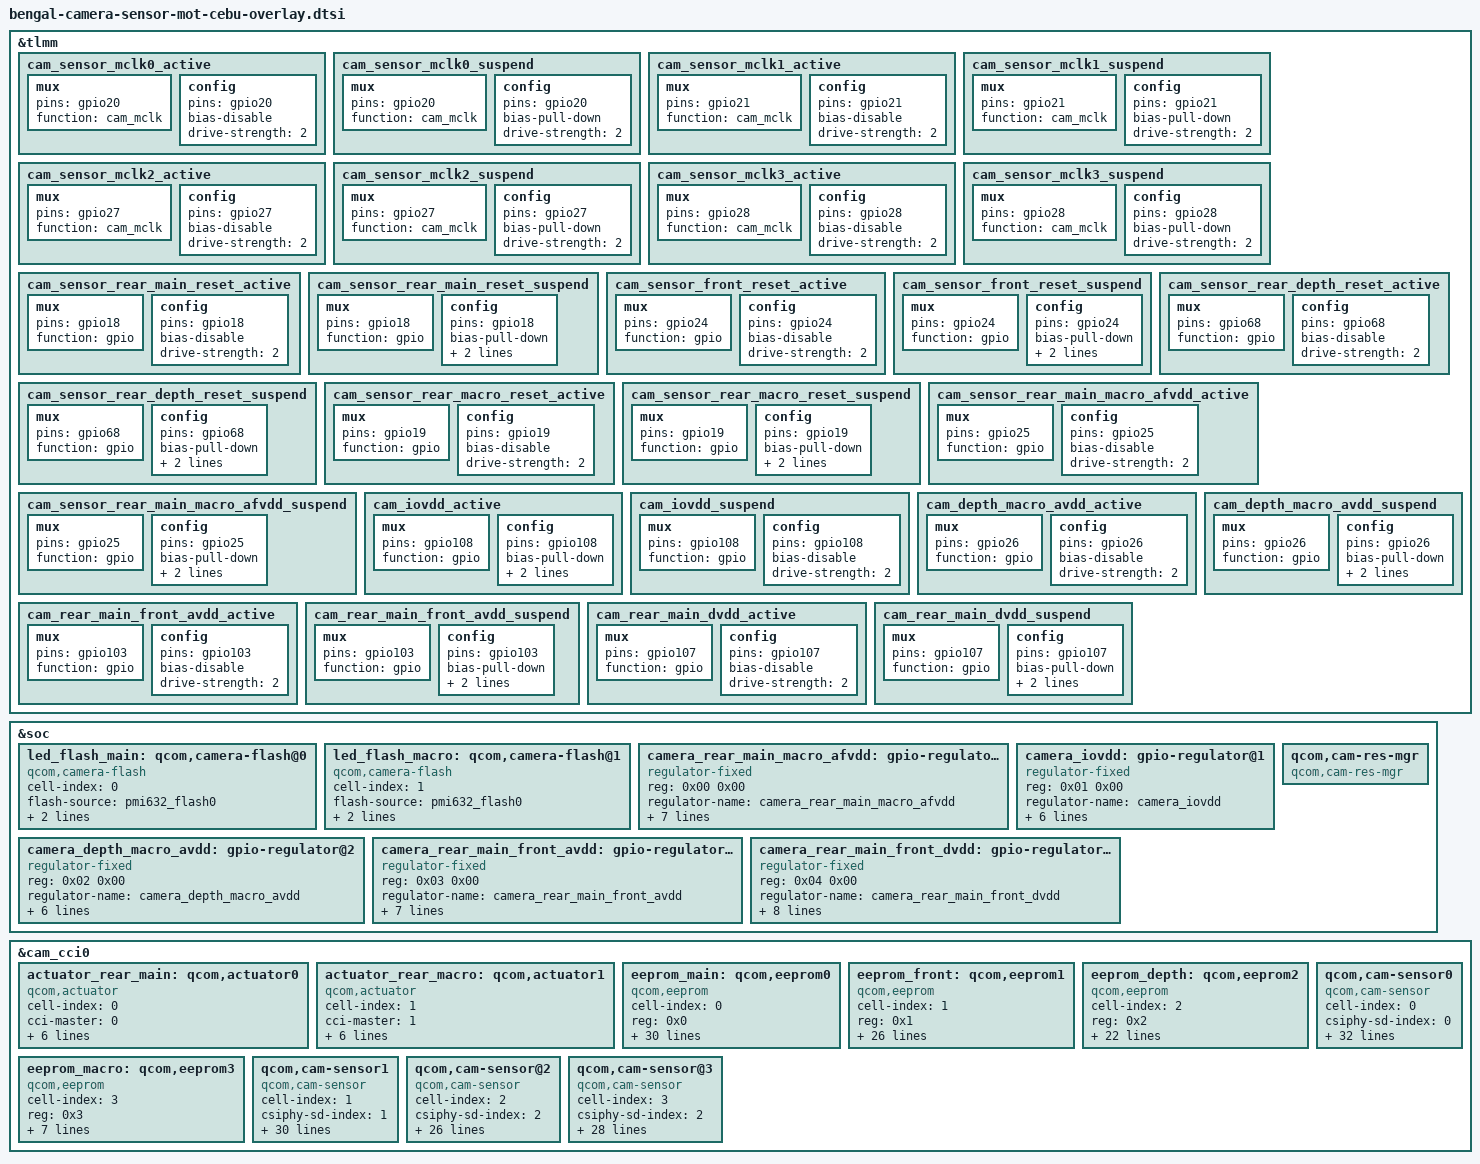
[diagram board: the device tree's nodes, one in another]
#include <dt-bindings/clock/qcom,gcc-bengal.h>


&tlmm {
	cam_sensor_mclk0_active: cam_sensor_mclk0_active {
		mux {
			pins = "gpio20";
			function = "cam_mclk";
		};

		config {
			pins = "gpio20";
			bias-disable; /* No PULL */
			drive-strength = <2>; /* 2 MA */
		};
	};

	cam_sensor_mclk0_suspend: cam_sensor_mclk0_suspend {
		mux {
			pins = "gpio20";
			function = "cam_mclk";
		};

		config {
			pins = "gpio20";
			bias-pull-down;
			drive-strength = <2>; /* 2 MA */
		};
	};

	cam_sensor_mclk1_active: cam_sensor_mclk1_active {
		mux {
			pins = "gpio21";
			function = "cam_mclk";
		};

		config {
			pins = "gpio21";
			bias-disable; /* No PULL */
			drive-strength = <2>; /* 2 MA */
		};
	};

	cam_sensor_mclk1_suspend: cam_sensor_mclk1_suspend {
		mux {
			pins = "gpio21";
			function = "cam_mclk";
		};

		config {
			pins = "gpio21";
			bias-pull-down;
			drive-strength = <2>; /* 2 MA */
		};
	};

	cam_sensor_mclk2_active: cam_sensor_mclk2_active {
		mux {
			pins = "gpio27";
			function = "cam_mclk";
		};

		config {
			pins = "gpio27";
			bias-disable; /* No PULL */
			drive-strength = <2>; /* 2 MA */
		};
	};

	cam_sensor_mclk2_suspend: cam_sensor_mclk2_suspend {
		mux {
			pins = "gpio27";
			function = "cam_mclk";
		};

		config {
			pins = "gpio27";
			bias-pull-down;
			drive-strength = <2>; /* 2 MA */
		};
	};

	cam_sensor_mclk3_active: cam_sensor_mclk3_active {
		mux {
			pins = "gpio28";
			function = "cam_mclk";
		};

		config {
			pins = "gpio28";
			bias-disable; /* No PULL */
			drive-strength = <2>; /* 2 MA */
		};
	};

	cam_sensor_mclk3_suspend: cam_sensor_mclk3_suspend {
		mux {
			pins = "gpio28";
			function = "cam_mclk";
		};

		config {
			pins = "gpio28";
			bias-pull-down;
			drive-strength = <2>; /* 2 MA */
		};
	};

	cam_sensor_rear_main_reset_active: cam_sensor_rear_main_reset_active {
		mux {
			pins = "gpio18";
			function = "gpio";
		};

		config {
			pins = "gpio18";
			bias-disable; /* No PULL */
			drive-strength = <2>; /* 2 MA */
		};
	};

	cam_sensor_rear_main_reset_suspend: cam_sensor_rear_main_reset_suspend {
		mux {
			pins = "gpio18";
			function = "gpio";
		};

		config {
			pins = "gpio18";
			bias-pull-down; /* PULL DOWN */
			drive-strength = <2>; /* 2 MA */
			output-low;
		};
	};

	cam_sensor_front_reset_active: cam_sensor_front_reset_active {
		mux {
			pins = "gpio24";
			function = "gpio";
		};

		config {
			pins = "gpio24";
			bias-disable; /* No PULL */
			drive-strength = <2>; /* 2 MA */
		};
	};

	cam_sensor_front_reset_suspend: cam_sensor_front_reset_suspend {
		mux {
			pins = "gpio24";
			function = "gpio";
		};

		config {
			pins = "gpio24";
			bias-pull-down; /* PULL DOWN */
			drive-strength = <2>; /* 2 MA */
			output-low;
		};
	};

	cam_sensor_rear_depth_reset_active: cam_sensor_rear_depth_reset_active {
		mux {
			pins = "gpio68";
			function = "gpio";
		};

		config {
			pins = "gpio68";
			bias-disable; /* No PULL */
			drive-strength = <2>; /* 2 MA */
		};
	};

	cam_sensor_rear_depth_reset_suspend: cam_sensor_rear_depth_reset_suspend {
		mux {
			pins = "gpio68";
			function = "gpio";
		};

		config {
			pins = "gpio68";
			bias-pull-down; /* PULL DOWN */
			drive-strength = <2>; /* 2 MA */
			output-low;
		};
	};

	cam_sensor_rear_macro_reset_active: cam_sensor_rear_macro_reset_active {
		mux {
			pins = "gpio19";
			function = "gpio";
		};

		config {
			pins = "gpio19";
			bias-disable; /* No PULL */
			drive-strength = <2>; /* 2 MA */
		};
	};

	cam_sensor_rear_macro_reset_suspend: cam_sensor_rear_macro_reset_suspend {
		mux {
			pins = "gpio19";
			function = "gpio";
		};

		config {
			pins = "gpio19";
			bias-pull-down; /* PULL DOWN */
			drive-strength = <2>; /* 2 MA */
			output-low;
		};
	};

	cam_sensor_rear_main_macro_afvdd_active: cam_sensor_rear_main_macro_afvdd_active {
		mux {
			pins = "gpio25";
			function = "gpio";
		};

		config {
			pins = "gpio25";
			bias-disable; /* No PULL */
			drive-strength = <2>; /* 2 MA */
		};
	};

	cam_sensor_rear_main_macro_afvdd_suspend: cam_sensor_rear_main_macro_afvdd_suspend {
		mux {
			pins = "gpio25";
			function = "gpio";
		};

		config {
			pins = "gpio25";
			bias-pull-down; /* PULL DOWN */
			drive-strength = <2>; /* 2 MA */
			output-low;
		};
	};

	cam_iovdd_active: cam_iovdd_active {
		mux {
			pins = "gpio108";
			function = "gpio";
		};

		config {
			pins = "gpio108";
			bias-pull-down; /* PULL DOWN */
			drive-strength = <2>; /* 2 MA */
			output-low;
		};
	};

	cam_iovdd_suspend: cam_iovdd_suspend {
		mux {
			pins = "gpio108";
			function = "gpio";
		};

		config {
			pins = "gpio108";
			bias-disable; /* No PULL */
			drive-strength = <2>; /* 2 MA */
		};
	};

	cam_depth_macro_avdd_active: cam_depth_macro_avdd_active {
		mux {
			pins = "gpio26";
			function = "gpio";
		};

		config {
			pins = "gpio26";
			bias-disable; /* No PULL */
			drive-strength = <2>; /* 2 MA */
		};
	};

	cam_depth_macro_avdd_suspend: cam_depth_macro_avdd_suspend {
		mux {
			pins = "gpio26";
			function = "gpio";
		};

		config {
			pins = "gpio26";
			bias-pull-down; /* PULL DOWN */
			drive-strength = <2>; /* 2 MA */
			output-low;
		};
	};

	cam_rear_main_front_avdd_active: cam_rear_main_front_avdd_active {
		mux {
			pins = "gpio103";
			function = "gpio";
		};

		config {
			pins = "gpio103";
			bias-disable; /* No PULL */
			drive-strength = <2>; /* 2 MA */
		};
	};

	cam_rear_main_front_avdd_suspend: cam_rear_main_front_avdd_suspend {
		mux {
			pins = "gpio103";
			function = "gpio";
		};

		config {
			pins = "gpio103";
			bias-pull-down; /* PULL DOWN */
			drive-strength = <2>; /* 2 MA */
			output-low;
		};
	};

	cam_rear_main_dvdd_active: cam_rear_main_dvdd_active {
		mux {
			pins = "gpio107";
			function = "gpio";
		};

		config {
			pins = "gpio107";
			bias-disable; /* No PULL */
			drive-strength = <2>; /* 2 MA */
		};
	};

	cam_rear_main_dvdd_suspend: cam_rear_main_dvdd_suspend {
		mux {
			pins = "gpio107";
			function = "gpio";
		};

		config {
			pins = "gpio107";
			bias-pull-down; /* PULL DOWN */
			drive-strength = <2>; /* 2 MA */
			output-low;
		};
	};
};

&soc {
	led_flash_main: qcom,camera-flash@0 {
		cell-index = <0>;
		compatible = "qcom,camera-flash";
		flash-source  = <&pmi632_flash0>;
		torch-source  = <&pmi632_torch0>;
		switch-source = <&pmi632_switch0>;
		status = "ok";
	};

	led_flash_macro: qcom,camera-flash@1 {
		cell-index = <1>;
		compatible = "qcom,camera-flash";
		flash-source  = <&pmi632_flash0>;
		torch-source  = <&pmi632_torch0>;
		switch-source = <&pmi632_switch0>;
		status = "ok";
	};

	camera_rear_main_macro_afvdd: gpio-regulator@0 {
		compatible = "regulator-fixed";
		reg = <0x00 0x00>;
		regulator-name = "camera_rear_main_macro_afvdd";
		regulator-min-microvolt = <2800000>;
		regulator-max-microvolt = <2800000>;
		regulator-enable-ramp-delay = <233>;
		enable-active-high;
		gpio = <&tlmm 25 0>;
		pinctrl-names = "default";
		pinctrl-0 = <&cam_sensor_rear_main_macro_afvdd_active>;
		//pinctrl-1 = <&cam_sensor_rear_main_macro_afvdd_suspend>;
	};

	camera_iovdd: gpio-regulator@1 {
		compatible = "regulator-fixed";
		reg = <0x01 0x00>;
		regulator-name = "camera_iovdd";
		regulator-min-microvolt = <1800000>;
		regulator-max-microvolt = <1800000>;
		regulator-enable-ramp-delay = <233>;
		//enable-active-high;//fff
		gpio = <&tlmm 108 0>;
		pinctrl-names = "default";
		pinctrl-0 = <&cam_iovdd_active>;
		//pinctrl-1 = <&cam_iovdd_suspend>;
		vin-supply = <&L9A>;
	};

	camera_depth_macro_avdd: gpio-regulator@2 {
		compatible = "regulator-fixed";
		reg = <0x02 0x00>;
		regulator-name = "camera_depth_macro_avdd";
		regulator-min-microvolt = <2800000>;
		regulator-max-microvolt = <2800000>;
		regulator-enable-ramp-delay = <233>;
		enable-active-high;
		gpio = <&tlmm 26 0>;
		pinctrl-names = "default";
		pinctrl-0 = <&cam_depth_macro_avdd_active>;
		//pinctrl-1 = <&cam_depth_macro_avdd_suspend>;
	};

	camera_rear_main_front_avdd: gpio-regulator@3 {
		compatible = "regulator-fixed";
		reg = <0x03 0x00>;
		regulator-name = "camera_rear_main_front_avdd";
		regulator-min-microvolt = <2800000>;
		regulator-max-microvolt = <2800000>;
		regulator-enable-ramp-delay = <233>;
		enable-active-high;
		gpio = <&tlmm 103 0>;
		pinctrl-names = "default";
		pinctrl-0 = <&cam_rear_main_front_avdd_active>;
		pinctrl-1 = <&cam_rear_main_front_avdd_suspend>;
	};
	/****************************************
	*	GPIO_80 low for rear main dvdd  *
	*	GPIO_80 high for front dvdd     *
	*****************************************/
	camera_rear_main_front_dvdd: gpio-regulator@4 {
		compatible = "regulator-fixed";
		reg = <0x04 0x00>;
		regulator-name = "camera_rear_main_front_dvdd";
		regulator-min-microvolt = <1200000>;
		regulator-max-microvolt = <1200000>;
		regulator-enable-ramp-delay = <233>;
		enable-active-high;
		gpio = <&tlmm 107 0>;
		pinctrl-names = "default";
		pinctrl-0 = <&cam_rear_main_dvdd_active>;
		pinctrl-1 = <&cam_rear_main_dvdd_suspend>;
		vin-supply = <&S6A>;
	};

	qcom,cam-res-mgr {
		compatible = "qcom,cam-res-mgr";
		status = "ok";
	};
};

&cam_cci0 {

	actuator_rear_main: qcom,actuator0 {
		cell-index = <0>;
		compatible = "qcom,actuator";
		cci-master = <0>;
		cam_vaf-supply = <&camera_rear_main_macro_afvdd>;
		regulator-names = "cam_vaf";
		rgltr-cntrl-support;
		rgltr-min-voltage = <2800000>;
		rgltr-max-voltage = <2800000>;
		rgltr-load-current = <100000>;
		status = "ok";
	};

	actuator_rear_macro: qcom,actuator1 {
		cell-index = <1>;
		compatible = "qcom,actuator";
		cci-master = <1>;
		cam_vaf-supply = <&camera_rear_main_macro_afvdd>;
		regulator-names = "cam_vaf";
		rgltr-cntrl-support;
		rgltr-min-voltage = <2800000>;
		rgltr-max-voltage = <2800000>;
		rgltr-load-current = <100000>;
		status = "ok";
	};

	/* ov64b rear main*/
	eeprom_main: qcom,eeprom0 {
		cell-index = <0>;
		reg = <0x0>;
		compatible = "qcom,eeprom";
		cam_vaf-supply = <&camera_rear_main_macro_afvdd>;
		cam_vio-supply = <&camera_iovdd>;
		cam_vana-supply = <&camera_rear_main_front_avdd>;
		cam_vdig-supply = <&camera_rear_main_front_dvdd>;
		cam_clk-supply = <&gcc_camss_top_gdsc>;
		regulator-names = "cam_vaf", "cam_vio", "cam_vana", "cam_vdig",
			"cam_clk";
		rgltr-cntrl-support;
		rgltr-min-voltage = <2800000 1800000 2800000 1200000 0>;
		rgltr-max-voltage = <2800000 1800000 2800000 1200000 0>;
		rgltr-load-current = <100000 120000 80000 1200000 0>;
		gpio-no-mux = <0>;
		pinctrl-names = "cam_default", "cam_suspend";
		pinctrl-0 = <&cam_sensor_mclk0_active
				&cam_sensor_rear_main_reset_active>;
		pinctrl-1 = <&cam_sensor_mclk0_suspend
				&cam_sensor_rear_main_reset_suspend>;
		gpios = <&tlmm 20 0>,
			<&tlmm 18 0>,
			<&tlmm 80 0>;
		gpio-reset = <1>;
		gpio-custom1 = <2>;//vdig active-low
		gpio-req-tbl-num = <0 1 2>;
		gpio-req-tbl-flags = <1 0 0>;
		gpio-req-tbl-label = "CAMIF_MCLK0",
					"CAM_RESET0",
					"CAM_DVDD_SEL0";
		cci-master = <0>;
		status = "ok";
		clocks = <&gcc GCC_CAMSS_MCLK0_CLK>;
		clock-names = "cam_clk";
		clock-cntl-level = "turbo";
		clock-rates = <24000000>;
	};

	/* ov16a1q front*/
	eeprom_front: qcom,eeprom1 {
		cell-index = <1>;
		reg = <0x1>;
		compatible = "qcom,eeprom";
		cam_vio-supply = <&camera_iovdd>;
		cam_vana-supply = <&camera_rear_main_front_avdd>;
		cam_vdig-supply = <&camera_rear_main_front_dvdd>;
		cam_clk-supply = <&gcc_camss_top_gdsc>;
		regulator-names = "cam_vio", "cam_vana", "cam_vdig",
			"cam_clk";
		rgltr-cntrl-support;
		rgltr-min-voltage = <1800000 2800000 1200000 0>;
		rgltr-max-voltage = <1800000 2800000 1200000 0>;
		rgltr-load-current = <120000 80000 1200000 0>;
		gpio-no-mux = <0>;
		pinctrl-names = "cam_default", "cam_suspend";
		pinctrl-0 = <&cam_sensor_mclk2_active
				&cam_sensor_front_reset_active>;
		pinctrl-1 = <&cam_sensor_mclk2_suspend
				&cam_sensor_front_reset_suspend>;
		gpios = <&tlmm 27 0>,
			<&tlmm 24 0>,
			<&tlmm 80 0>;
		gpio-reset = <1>;
		gpio-custom1 = <2>;/*vdig active-high */
		gpio-req-tbl-num = <0 1 2>;
		gpio-req-tbl-flags = <1 0 0>;
		gpio-req-tbl-label = "CAMIF_MCLK2",
					"CAM_RESET1",
					"CAM_DVDD_SEL1";
		cci-master = <0>;
		status = "ok";
		clocks = <&gcc GCC_CAMSS_MCLK2_CLK>;
		clock-names = "cam_clk";
		clock-cntl-level = "turbo";
		clock-rates = <24000000>;
	};

 	/* ov02b1b rear depth*/
	eeprom_depth: qcom,eeprom2 {
		cell-index = <2>;
		reg = <0x2>;
		compatible = "qcom,eeprom";
		cam_vio-supply = <&camera_iovdd>;
		cam_vana-supply = <&camera_depth_macro_avdd>;
		cam_clk-supply = <&gcc_camss_top_gdsc>;
		regulator-names = "cam_vio", "cam_vana", "cam_clk";
		rgltr-cntrl-support;
		rgltr-min-voltage = <1800000 2800000 0>;
		rgltr-max-voltage = <1800000 2800000 0>;
		rgltr-load-current = <120000 80000 0>;
		gpio-no-mux = <0>;
		pinctrl-names = "cam_default", "cam_suspend";
		pinctrl-0 = <&cam_sensor_mclk3_active
				&cam_sensor_rear_depth_reset_active>;
		pinctrl-1 = <&cam_sensor_mclk3_suspend
				&cam_sensor_rear_depth_reset_suspend>;
		gpios = <&tlmm 28 0>,
			<&tlmm 68 0>;
		gpio-reset = <1>;
		gpio-req-tbl-num = <0 1>;
		gpio-req-tbl-flags = <1 0>;
		gpio-req-tbl-label = "CAMIF_MCLK3",
					"CAM_RESET2";
		cci-master = <1>;
		status = "ok";
		clocks = <&gcc GCC_CAMSS_MCLK3_CLK>;
		clock-names = "cam_clk";
		clock-cntl-level = "turbo";
		clock-rates = <24000000>;
	};

	/* ov02b10 rear macro*/
	eeprom_macro: qcom,eeprom3 {
		cell-index = <3>;
		reg = <0x3>;
		compatible = "qcom,eeprom";
		cci-master = <1>;
		cam_vio-supply = <&camera_iovdd>;
		regulator-names = "cam_vio";
		rgltr-cntrl-support;
		rgltr-min-voltage = <1800000>;
		rgltr-max-voltage = <1800000>;
		rgltr-load-current = <120000>;
		status = "ok";
	};

	/* ov64b rear main */
	qcom,cam-sensor0 {
		cell-index = <0>;
		compatible = "qcom,cam-sensor";
		csiphy-sd-index = <0>;
		sensor-position-roll = <90>;
		sensor-position-pitch = <0>;
		sensor-position-yaw = <180>;
		actuator-src = <&actuator_rear_main>;
		led-flash-src = <&led_flash_main>;
		eeprom-src = <&eeprom_main>;
		cam_vio-supply = <&camera_iovdd>;
		cam_vana-supply = <&camera_rear_main_front_avdd>;
		cam_vdig-supply = <&camera_rear_main_front_dvdd>;
		cam_clk-supply = <&gcc_camss_top_gdsc>;
		regulator-names = "cam_vio", "cam_vana", "cam_vdig",
			"cam_clk";
		rgltr-cntrl-support;
		rgltr-min-voltage = <1800000 2800000 1200000 0>;
		rgltr-max-voltage = <1800000 2800000 1200000 0>;
		rgltr-load-current = <120000 80000 1200000 0>;
		gpio-no-mux = <0>;
		pinctrl-names = "cam_default", "cam_suspend";
		pinctrl-0 = <&cam_sensor_mclk0_active
				&cam_sensor_rear_main_reset_active>;
		pinctrl-1 = <&cam_sensor_mclk0_suspend
				&cam_sensor_rear_main_reset_suspend>;
		gpios = <&tlmm 20 0>,
			<&tlmm 18 0>,
			<&tlmm 80 0>;
		gpio-reset = <1>;
		gpio-custom1 = <2>;//vdig active-low
		gpio-req-tbl-num = <0 1 2>;
		gpio-req-tbl-flags = <1 0 0>;
		gpio-req-tbl-label = "CAMIF_MCLK0",
					"CAM_RESET0",
					"CAM_DVDD_SEL0";
		cci-master = <0>;
		status = "ok";
		clocks = <&gcc GCC_CAMSS_MCLK0_CLK>;
		clock-names = "cam_clk";
		clock-cntl-level = "turbo";
		clock-rates = <24000000>;
	};

	 /* ov16a1q & s5k4h7 front */
	qcom,cam-sensor1 {
		cell-index = <1>;
		compatible = "qcom,cam-sensor";
		csiphy-sd-index = <1>;
		sensor-position-roll = <270>;
		sensor-position-pitch = <0>;
		sensor-position-yaw = <0>;
		eeprom-src = <&eeprom_front>;
		cam_vio-supply = <&camera_iovdd>;
		cam_vana-supply = <&camera_rear_main_front_avdd>;
		cam_vdig-supply = <&camera_rear_main_front_dvdd>;
		cam_clk-supply = <&gcc_camss_top_gdsc>;
		regulator-names = "cam_vio", "cam_vana", "cam_vdig",
			"cam_clk";
		rgltr-cntrl-support;
		rgltr-min-voltage = <1800000 2800000 1200000 0>;
		rgltr-max-voltage = <1800000 2800000 1200000 0>;
		rgltr-load-current = <120000 80000 1200000 0>;
		gpio-no-mux = <0>;
		pinctrl-names = "cam_default", "cam_suspend";
		pinctrl-0 = <&cam_sensor_mclk2_active
				&cam_sensor_front_reset_active>;
		pinctrl-1 = <&cam_sensor_mclk2_suspend
				&cam_sensor_front_reset_suspend>;
		gpios = <&tlmm 27 0>,
			<&tlmm 24 0>,
			<&tlmm 80 0>;
		gpio-reset = <1>;
		gpio-custom1 = <2>;/*vdig active-high */
		gpio-req-tbl-num = <0 1 2>;
		gpio-req-tbl-flags = <1 0 0>;
		gpio-req-tbl-label = "CAMIF_MCLK2",
					"CAM_RESET1",
					"CAM_DVDD_SEL1";
		cci-master = <0>;
		status = "ok";
		clocks = <&gcc GCC_CAMSS_MCLK2_CLK>;
		clock-names = "cam_clk";
		clock-cntl-level = "turbo";
		clock-rates = <24000000>;
	};

	 /* ov02b1b depth*/

	qcom,cam-sensor@2 {
		cell-index = <2>;
		compatible = "qcom,cam-sensor";
		csiphy-sd-index = <2>;
		sensor-position-roll = <90>;
		sensor-position-pitch = <0>;
		sensor-position-yaw = <180>;
		eeprom-src = <&eeprom_depth>;
		cam_vio-supply = <&camera_iovdd>;
		cam_vana-supply = <&camera_depth_macro_avdd>;
		cam_clk-supply = <&gcc_camss_top_gdsc>;
		regulator-names = "cam_vio", "cam_vana", "cam_clk";
		rgltr-cntrl-support;
		rgltr-min-voltage = <1800000 2800000 0>;
		rgltr-max-voltage = <1800000 2800000 0>;
		rgltr-load-current = <120000 80000 0>;
		gpio-no-mux = <0>;
		pinctrl-names = "cam_default", "cam_suspend";
		pinctrl-0 = <&cam_sensor_mclk3_active
				&cam_sensor_rear_depth_reset_active>;
		pinctrl-1 = <&cam_sensor_mclk3_suspend
				&cam_sensor_rear_depth_reset_suspend>;
		gpios = <&tlmm 28 0>,
			<&tlmm 68 0>;
		gpio-reset = <1>;
		gpio-req-tbl-num = <0 1>;
		gpio-req-tbl-flags = <1 0>;
		gpio-req-tbl-label = "CAMIF_MCLK3",
					"CAM_RESET2";
		cci-master = <1>;
		status = "ok";
		clocks = <&gcc GCC_CAMSS_MCLK3_CLK>;
		clock-names = "cam_clk";
		clock-cntl-level = "turbo";
		clock-rates = <24000000>;
	};

	 /* ov02b10 macro*/
	qcom,cam-sensor@3 {
		cell-index = <3>;
		compatible = "qcom,cam-sensor";
		csiphy-sd-index = <2>;
		sensor-position-roll = <90>;
		sensor-position-pitch = <0>;
		sensor-position-yaw = <180>;
		actuator-src = <&actuator_rear_macro>;
		led-flash-src = <&led_flash_macro>;
		eeprom-src = <&eeprom_macro>;
		cam_vio-supply = <&camera_iovdd>;
		cam_vana-supply = <&camera_depth_macro_avdd>;
		cam_clk-supply = <&gcc_camss_top_gdsc>;
		regulator-names = "cam_vio", "cam_vana", "cam_clk";
		rgltr-cntrl-support;
		rgltr-min-voltage = <1800000 2800000 0>;
		rgltr-max-voltage = <1800000 2800000 0>;
		rgltr-load-current = <120000 80000 0>;
		gpio-no-mux = <0>;
		pinctrl-names = "cam_default", "cam_suspend";
		pinctrl-0 = <&cam_sensor_mclk1_active
				&cam_sensor_rear_macro_reset_active>;
		pinctrl-1 = <&cam_sensor_mclk1_suspend
				&cam_sensor_rear_macro_reset_suspend>;
		gpios = <&tlmm 21 0>,
			<&tlmm 19 0>;
		gpio-reset = <1>;
		gpio-req-tbl-num = <0 1>;
		gpio-req-tbl-flags = <1 0>;
		gpio-req-tbl-label = "CAMIF_MCLK1",
					"CAM_PWDN";
		cci-master = <1>;
		status = "ok";
		clocks = <&gcc GCC_CAMSS_MCLK1_CLK>;
		clock-names = "cam_clk";
		clock-cntl-level = "turbo";
		clock-rates = <24000000>;
	};
};
